# PIC32CM2532JH01032 device description
Architecture: CORTEX-M0PLUS; Family: PIC32CM; Series: PIC32CMJH01
Registers are 32-bit, read-write, reset 0x0 unless marked. A register's access mark holds for its fields unless they carry their own. Offsets are from the block's base; [hi:lo] are bit positions; {n}, {i} and the like mark numbered series.

## DIVAS — Divide and Square Root Accelerator
Instances: DIVAS 0x48000000, DIVAS_IOBUS 0x60000200
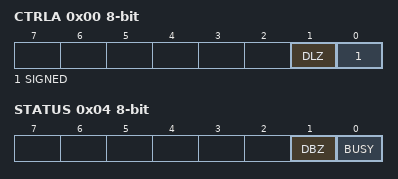
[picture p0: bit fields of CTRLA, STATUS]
0x00 CTRLA 8-bit — Control
  [1] DLZ — Disable Leading Zero Optimization
  [0] SIGNED
0x04 STATUS 8-bit
  [1] DBZ — Writing a one to this bit clears DBZ to zero
  [0] BUSY — DIVAS Accelerator Busy
0x08 DIVIDEND
0x0C DIVISOR
0x10 RESULT ro
0x14 REM ro — Remainder
0x18 SQRNUM — Square Root Input

## DMAC_DESCRIPTOR — Direct Memory Access Controller
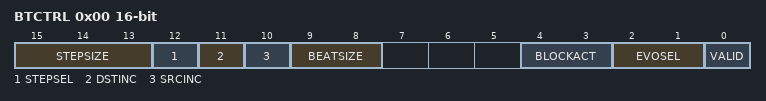
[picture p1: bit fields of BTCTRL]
0x00 BTCTRL 16-bit — Block Transfer Control
  [15:13] STEPSIZE — Address Increment Step Size
    0=Next ADDR = ADDR + (Beat Size in byte) * 1; 1=X2 (Next ADDR = ADDR + (Beat Size in byte) * 2); 2=X4 (Next ADDR = ADDR + (Beat Size in byte) * 4); 3=X8 (Next ADDR = ADDR + (Beat Size in byte) * 8); 4=X16 (Next ADDR = ADDR + (Beat Size in byte) * 16); 5=X32 (Next ADDR = ADDR + (Beat Size in byte) * 32); 6=X64 (Next ADDR = ADDR + (Beat Size in byte) * 64); 7=X128 (Next ADDR = ADDR + (Beat Size in byte) * 128)
  [12] STEPSEL — Step Selection
    0=DST (Step size settings apply to the destination address); 1=SRC (Step size settings apply to the source address)
  [11] DSTINC — Destination Address Increment Enable
  [10] SRCINC — Source Address Increment Enable
  [9:8] BEATSIZE
    0=BYTE (8-bit bus transfer); 1=HWORD (16-bit bus transfer); 2=WORD (32-bit bus transfer)
  [4:3] BLOCKACT — Block Action
    0=NOACT (Channel will be disabled if it is the last block transfer in the transaction); 1=INT (Channel will be disabled if it is the last block transfer in the transaction and block interrupt); 2=SUSPEND (Channel suspend operation is completed); 3=BOTH (Both channel suspend operation and block interrupt)
  [2:1] EVOSEL — Event Output Selection
    0=DISABLE (Event generation disabled); 1=BLOCK (Event strobe when block transfer complete); 3=BEAT (Event strobe when beat transfer complete)
  [0] VALID — Descriptor Valid
0x02 BTCNT 16-bit reset not defined — Block Transfer Count
0x04 SRCADDR reset not defined — Block Transfer Source Address
  [31:0] SRCADDR — Transfer Source Address
0x08 DSTADDR reset not defined — Block Transfer Destination Address
  [31:0] DSTADDR — Transfer Destination Address
0x0C DESCADDR reset not defined — Next Descriptor Address

## DSU — Device Service Unit
Instances: DSU 0x41002000, DSU_EXT 0x41002100
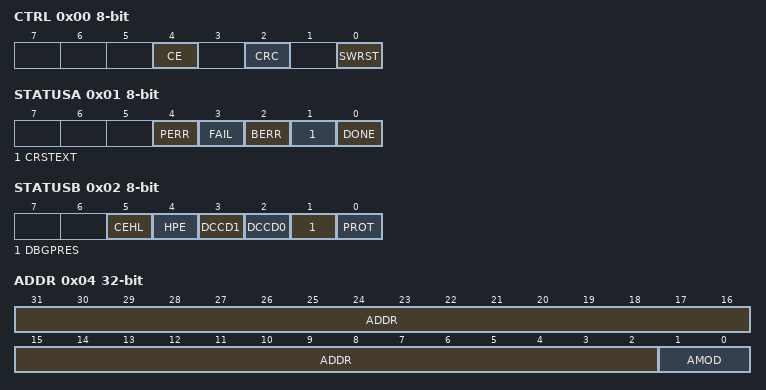
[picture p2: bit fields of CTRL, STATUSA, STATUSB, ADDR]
0x00 CTRL 8-bit wo — Control
  [4] CE — Chip-Erase
  [2] CRC — 32-bit Cyclic Redundancy Code
  [0] SWRST — Software Reset
0x01 STATUSA 8-bit
  [4] PERR — Protection Error
  [3] FAIL — Failure
  [2] BERR — Bus Error
  [1] CRSTEXT — CPU Reset Phase Extension
  [0] DONE
0x02 STATUSB 8-bit ro
  [5] CEHL — Chip Erase Hard Lock
  [4] HPE — Hot-Plugging Enable
  [3] DCCD1 — Debug Communication Channel 1 Dirty
  [2] DCCD0 — Debug Communication Channel 0 Dirty
  [1] DBGPRES — Debugger Present
  [0] PROT — Protected
0x04 ADDR — Address
  [31:2] ADDR — Address
  [1:0] AMOD — Access Mode
0x08 LENGTH
  [31:2] LENGTH
0x0C DATA
{0x10+4i} DCC[{i}] (i=0..1) — Debug Communication Channel n
  [31:0] DATA
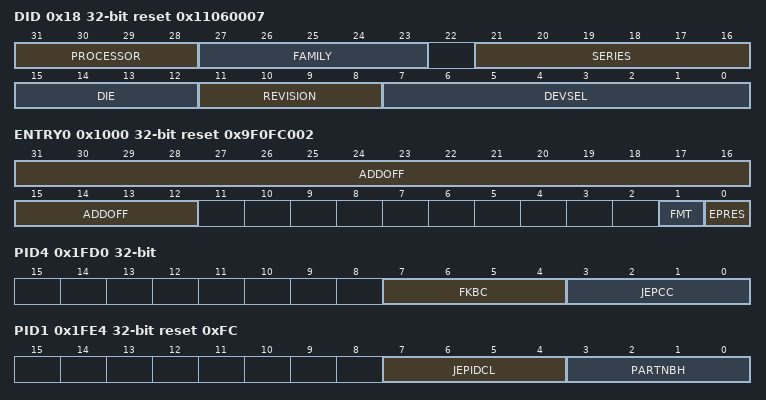
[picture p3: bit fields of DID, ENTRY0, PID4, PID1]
0x18 DID ro reset 0x11060007 — Device Identification
  [31:28] PROCESSOR
    1=Cortex-M0+
  [27:23] FAMILY
    2=5V Industrial
  [21:16] SERIES
    6=JH00_JH01 (PIC32CM JH00 and PIC32CM JH01)
  [15:12] DIE — Die Number
  [11:8] REVISION — Revision Number
  [7:0] DEVSEL — Device Select
    0=512KB_64KB_100PIN_CAN (512 KB Flash / 64 KB SRAM / 100-pin / CAN); 1=512KB_64KB_64PIN_CAN (512 KB Flash / 64 KB SRAM / 64-pin / CAN); 2=512KB_64KB_48PIN_CAN (512 KB Flash / 64 KB SRAM / 48-pin / CAN); 3=512KB_64KB_32PIN_CAN (512 KB Flash / 64 KB SRAM / 32-pin / CAN); 4=256KB_32KB_100PIN_CAN (256 KB Flash / 32 KB SRAM / 100-pin / CAN); 5=256KB_32KB_64PIN_CAN (256 KB Flash / 32 KB SRAM / 64-pin / CAN); 6=256KB_32KB_48PIN_CAN (256 KB Flash / 32 KB SRAM / 48-pin / CAN); 7=256KB_32KB_32PIN_CAN (256 KB Flash / 32 KB SRAM / 32-pin / CAN); 13=256KB_32KB_100PIN_NOCAN (256 KB Flash / 32 KB SRAM / 100-pin / No CAN); 14=512KB_64KB_100PIN_NOCAN (512 KB Flash / 64 KB SRAM / 100-pin / No CAN); 15=512KB_64KB_64PIN_NOCAN (512 KB Flash / 64 KB SRAM / 64-pin / No CAN); 16=256KB_32KB_64PIN_NOCAN (256 KB Flash / 32 KB SRAM / 64-pin / No CAN); 19=256KB_32KB_48PIN_NOCAN (256 KB Flash / 32 KB SRAM / 48-pin / No CAN); 20=512KB_64KB_48PIN_NOCAN (512 KB Flash / 64 KB SRAM / 48-pin / No CAN); 21=512KB_64KB_32PIN_NOCAN (512 KB Flash / 64 KB SRAM / 32-pin / No CAN); 22=256KB_32KB_32PIN_NOCAN (256 KB Flash / 32 KB SRAM / 32-pin / No CAN)
0x1000 ENTRY0 ro reset 0x9F0FC002 — CoreSight ROM Table Entry 0
  [31:12] ADDOFF — Address Offset
  [1] FMT — Format
  [0] EPRES — Entry Present
0x1004 ENTRY1 ro — CoreSight ROM Table Entry 1
0x1008 END ro — CoreSight ROM Table End
  [31:0] END — End Marker
0x1FCC MEMTYPE ro — CoreSight ROM Table Memory Type
  [0] SMEMP — System Memory Present
0x1FD0 PID4 ro — Peripheral Identification 4
  [7:4] FKBC — 4KB count
  [3:0] JEPCC — JEP-106 Continuation Code
{0x1FC0+4i} PID{i} ro (i=5..7) — Peripheral Identification {i}
0x1FE0 PID0 ro reset 0xD0 — Peripheral Identification 0
  [7:0] PARTNBL — Part Number Low
0x1FE4 PID1 ro reset 0xFC — Peripheral Identification 1
  [7:4] JEPIDCL — Low part of the JEP-106 Identity Code
  [3:0] PARTNBH — Part Number High
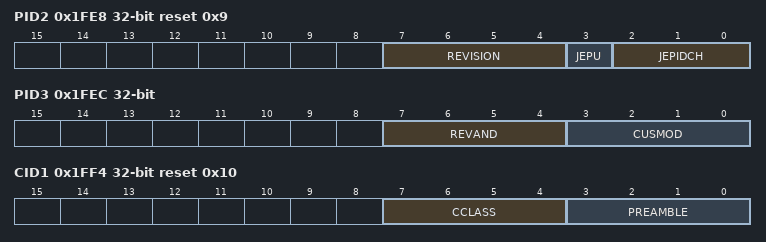
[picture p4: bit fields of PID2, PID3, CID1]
0x1FE8 PID2 ro reset 0x9 — Peripheral Identification 2
  [7:4] REVISION — Revision Number
  [3] JEPU — JEP-106 Identity Code is used
  [2:0] JEPIDCH — JEP-106 Identity Code High
0x1FEC PID3 ro — Peripheral Identification 3
  [7:4] REVAND — Revision Number
  [3:0] CUSMOD — ARM CUSMOD
0x1FF0 CID0 ro reset 0xD — Component Identification 0
  [7:0] PREAMBLEB0 — Preamble Byte 0
0x1FF4 CID1 ro reset 0x10 — Component Identification 1
  [7:4] CCLASS — Component Class
  [3:0] PREAMBLE
0x1FF8 CID2 ro reset 0x5 — Component Identification 2
  [7:0] PREAMBLEB2 — Preamble Byte 2
0x1FFC CID3 ro reset 0xB1 — Component Identification 3
  [7:0] PREAMBLEB3 — Preamble Byte 3

## Notices in the file
Copyright (c) 2019 Microchip Technology Inc.
SPDX-License-Identifier: Apache-2.0
Licensed under the Apache License, Version 2.0 (the "License");
you may not use this file except in compliance with the License.
You may obtain a copy of the License at
http://www.apache.org/licenses/LICENSE-2.0
Unless required by applicable law or agreed to in writing, software
distributed under the License is distributed on an "AS IS" BASIS,
WITHOUT WARRANTIES OR CONDITIONS OF ANY KIND, either express or implied.
See the License for the specific language governing permissions and
limitations under the License.
